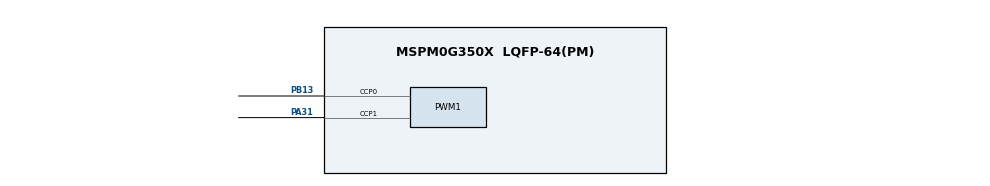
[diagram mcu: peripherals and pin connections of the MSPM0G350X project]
// @cliArgs --device "MSPM0G350X" --package "LQFP-64(PM)" --part "Default"
// @cliArgs --board /ti/boards/LP_MSPM0G3507 --rtos nortos

/**
 * Import the modules used in this configuration.
 */
const PWM    = scripting.addModule("/ti/driverlib/PWM", {}, false);
const PWM1   = PWM.addInstance();
const SYSCTL = scripting.addModule("/ti/driverlib/SYSCTL");

/**
 * Write custom configuration values to the imported modules.
 */
PWM1.$name                      = "PWM_0";
PWM1.timerCount                 = 512000;
PWM1.peripheral.$assign         = "TIMG12";
PWM1.peripheral.ccp0Pin.$assign = "PB13";
PWM1.peripheral.ccp1Pin.$assign = "PA31";
PWM1.PWM_CHANNEL_0.$name        = "ti_driverlib_pwm_PWMTimerCC0";
PWM1.PWM_CHANNEL_0.dutyCycle    = 75;
PWM1.PWM_CHANNEL_1.$name        = "ti_driverlib_pwm_PWMTimerCC1";
PWM1.PWM_CHANNEL_1.dutyCycle    = 50;

const Board = scripting.addModule("/ti/driverlib/Board", {}, false);

SYSCTL.forceDefaultClkConfig = true;
SYSCTL.clockTreeEn  = true;
